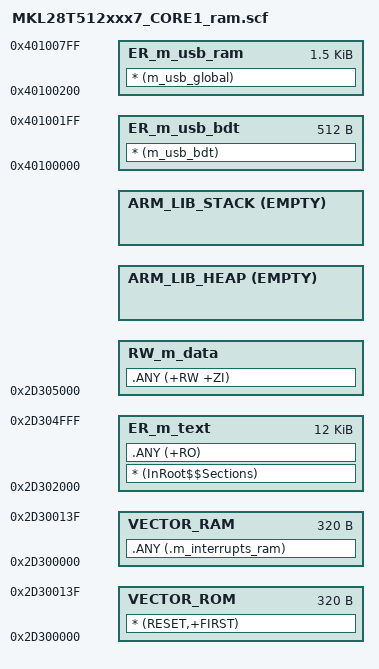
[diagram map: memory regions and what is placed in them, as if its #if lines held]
#! armcc -E
/*
** ###################################################################
**     Processors:          MKL28T512VDC7_CORE1
**                          MKL28T512VLH7_CORE1
**                          MKL28T512VLL7_CORE1
**                          MKL28T512VMP7_CORE1
**
**     Compiler:            Keil ARM C/C++ Compiler
**     Reference manual:    MKL28TRM, Rev. 0, Sept 30, 2015
**     Version:             rev. 1.7, 2015-05-16
**     Build:               b151010
**
**     Abstract:
**         Linker file for the Keil ARM C/C++ Compiler
**
**     Copyright (c) 2015 Freescale Semiconductor, Inc.
**     All rights reserved.
**
**     Redistribution and use in source and binary forms, with or without modification,
**     are permitted provided that the following conditions are met:
**
**     o Redistributions of source code must retain the above copyright notice, this list
**       of conditions and the following disclaimer.
**
**     o Redistributions in binary form must reproduce the above copyright notice, this
**       list of conditions and the following disclaimer in the documentation and/or
**       other materials provided with the distribution.
**
**     o Neither the name of Freescale Semiconductor, Inc. nor the names of its
**       contributors may be used to endorse or promote products derived from this
**       software without specific prior written permission.
**
**     THIS SOFTWARE IS PROVIDED BY THE COPYRIGHT HOLDERS AND CONTRIBUTORS "AS IS" AND
**     ANY EXPRESS OR IMPLIED WARRANTIES, INCLUDING, BUT NOT LIMITED TO, THE IMPLIED
**     WARRANTIES OF MERCHANTABILITY AND FITNESS FOR A PARTICULAR PURPOSE ARE
**     DISCLAIMED. IN NO EVENT SHALL THE COPYRIGHT HOLDER OR CONTRIBUTORS BE LIABLE FOR
**     ANY DIRECT, INDIRECT, INCIDENTAL, SPECIAL, EXEMPLARY, OR CONSEQUENTIAL DAMAGES
**     (INCLUDING, BUT NOT LIMITED TO, PROCUREMENT OF SUBSTITUTE GOODS OR SERVICES;
**     LOSS OF USE, DATA, OR PROFITS; OR BUSINESS INTERRUPTION) HOWEVER CAUSED AND ON
**     ANY THEORY OF LIABILITY, WHETHER IN CONTRACT, STRICT LIABILITY, OR TORT
**     (INCLUDING NEGLIGENCE OR OTHERWISE) ARISING IN ANY WAY OUT OF THE USE OF THIS
**     SOFTWARE, EVEN IF ADVISED OF THE POSSIBILITY OF SUCH DAMAGE.
**
**     http:                 www.freescale.com
**     mail:                 support@freescale.com
**
** ###################################################################
*/

#define m_interrupts_start             0x2D300000
#define m_interrupts_size              0x00000140

#define m_text_start                   0x2D302000
#define m_text_size                    0x00003000

#define m_data_start                   0x2D305000
#define m_data_size                    0x00003000

#if (defined(__usb_use_usbram__))
#define m_usb_sram_start               0x40100000
#define m_usb_sram_size                0x00000800
#endif

/* USB BDT size */
#define usb_bdt_size                   0x200
/* Sizes */
#if (defined(__stack_size__))
  #define Stack_Size                   __stack_size__
#else
  #define Stack_Size                   0x0400
#endif

#if (defined(__heap_size__))
  #define Heap_Size                    __heap_size__
#else
  #define Heap_Size                    0x0400
#endif

LR_m_text m_text_start m_text_size {   ; load region size_region
  ER_m_text m_text_start m_text_size { ; load address = execution address
    * (InRoot$$Sections)
    .ANY (+RO)
  }
  RW_m_data m_data_start m_data_size-Stack_Size-Heap_Size { ; RW data
    .ANY (+RW +ZI)
  }
  ARM_LIB_HEAP +0 EMPTY Heap_Size {    ; Heap region growing up
  }
  ARM_LIB_STACK m_data_start+m_data_size EMPTY -Stack_Size { ; Stack region growing down
  }
}

LR_m_interrupts m_interrupts_start m_interrupts_size {
  VECTOR_ROM m_interrupts_start m_interrupts_size { ; load address = execution address
    * (RESET,+FIRST)
  }
}

LR_m_interrupts_ram m_interrupts_start m_interrupts_size {
  VECTOR_RAM m_interrupts_start m_interrupts_size { ; load address = execution address
    .ANY (.m_interrupts_ram)
  }
}

#if (defined(__usb_use_usbram__))
LR_m_usb_bdt m_usb_sram_start usb_bdt_size {
  ER_m_usb_bdt m_usb_sram_start usb_bdt_size {
    * (m_usb_bdt)
  }
}

LR_m_usb_ram (m_usb_sram_start + usb_bdt_size) (m_usb_sram_size - usb_bdt_size) {
  ER_m_usb_ram (m_usb_sram_start + usb_bdt_size) (m_usb_sram_size - usb_bdt_size) {
    * (m_usb_global)
  }
}
#endif

